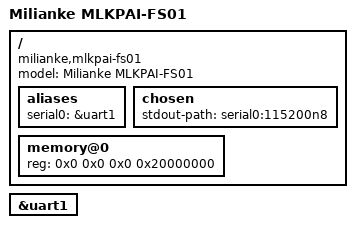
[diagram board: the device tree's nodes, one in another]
// SPDX-License-Identifier: GPL-2.0 OR MIT
/*
 * Copyright (C) 2025 Junhui Liu <junhui.liu@pigmoral.tech>
 */

#include "dr1v90.dtsi"

/ {
	model = "Milianke MLKPAI-FS01";
	compatible = "milianke,mlkpai-fs01", "anlogic,dr1v90";

	aliases {
		serial0 = &uart1;
	};

	chosen {
		stdout-path = "serial0:115200n8";
	};

	memory@0 {
		device_type = "memory";
		reg = <0x0 0x0 0x0 0x20000000>;
	};
};

&uart1 {
	status = "okay";
};
